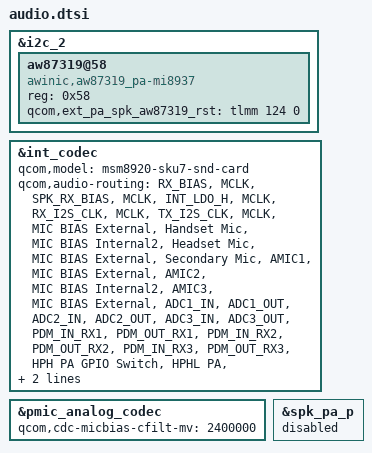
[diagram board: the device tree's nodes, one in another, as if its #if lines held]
&i2c_2  {
	aw87319@58{ /*AW87319 PA*/
#ifdef CONFIG_SND_SOC_AW87319_MI8937
		compatible = "awinic,aw87319_pa-mi8937";
#else
		compatible = "awinic,aw87319_pa";
#endif
		reg = <0x58>;
		qcom,ext_pa_spk_aw87319_rst = <&tlmm 124 0>;
	};
};

&int_codec {
	qcom,model = "msm8920-sku7-snd-card";
	qcom,audio-routing =
		"RX_BIAS", "MCLK",
		"SPK_RX_BIAS", "MCLK",
		"INT_LDO_H", "MCLK",
		"RX_I2S_CLK", "MCLK",
		"TX_I2S_CLK", "MCLK",
		"MIC BIAS External", "Handset Mic",
		"MIC BIAS Internal2", "Headset Mic",
		"MIC BIAS External", "Secondary Mic",
		"AMIC1", "MIC BIAS External",
		"AMIC2", "MIC BIAS Internal2",
		"AMIC3", "MIC BIAS External",
		"ADC1_IN", "ADC1_OUT",
		"ADC2_IN", "ADC2_OUT",
		"ADC3_IN", "ADC3_OUT",
		"PDM_IN_RX1", "PDM_OUT_RX1",
		"PDM_IN_RX2", "PDM_OUT_RX2",
		"PDM_IN_RX3", "PDM_OUT_RX3"
#ifdef MI8937_V2
		,
		"HPH PA GPIO Switch", "HPHL PA",
		"HPH PA GPIO Switch", "HPHR PA",
		"MI8937 AW87319 PA SPK Switch", "HPHR PA"
#endif
		;
};

&pmic_analog_codec {
	qcom,cdc-micbias-cfilt-mv = <2400000>;
};

#ifdef MI8937_V2
&spk_pa_p {
	status = "disabled";
};
#endif
